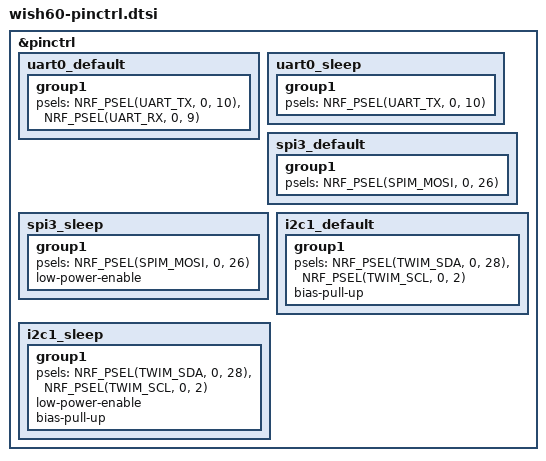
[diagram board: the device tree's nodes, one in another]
&pinctrl {
  uart0_default: uart0_default {
    group1 {
      psels = <NRF_PSEL(UART_TX, 0, 10)>, <NRF_PSEL(UART_RX, 0, 9)>;
    };
  };

  uart0_sleep: uart0_sleep {
    group1 {
      psels = <NRF_PSEL(UART_TX, 0, 10)>;
    };
  };

  /* ws2812(네오픽셀) — SPIM MOSI 만 쓴다. wish60 회로: P0.26 */
  spi3_default: spi3_default {
    group1 {
      psels = <NRF_PSEL(SPIM_MOSI, 0, 26)>;
    };
  };

  spi3_sleep: spi3_sleep {
    group1 {
      psels = <NRF_PSEL(SPIM_MOSI, 0, 26)>;
      low-power-enable;
    };
  };

  /* MAX17048 연료게이지 — SDA P0.28 / SCL P0.02 (zmk-wish60 참고, 회로도 미검증) */
  i2c1_default: i2c1_default {
    group1 {
      psels = <NRF_PSEL(TWIM_SDA, 0, 28)>,
              <NRF_PSEL(TWIM_SCL, 0, 2)>;
      bias-pull-up;
    };
  };

  i2c1_sleep: i2c1_sleep {
    group1 {
      psels = <NRF_PSEL(TWIM_SDA, 0, 28)>,
              <NRF_PSEL(TWIM_SCL, 0, 2)>;
      low-power-enable;
      bias-pull-up;
    };
  };
};
